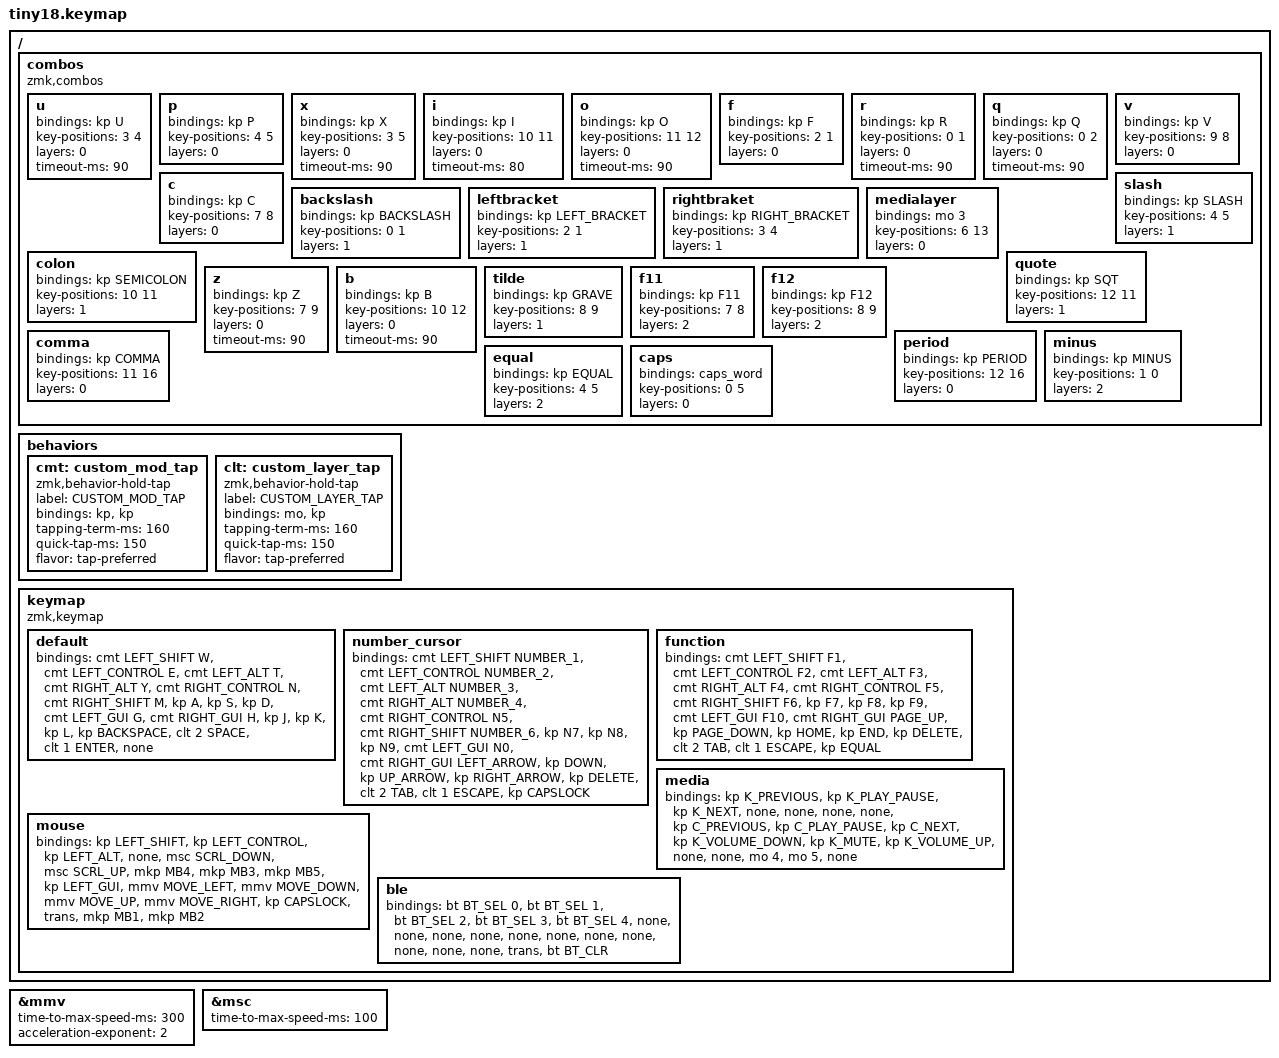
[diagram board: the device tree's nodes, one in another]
#include <input/processors.dtsi>
#include <dt-bindings/zmk/input_transform.h>
#include <zephyr/dt-bindings/input/input-event-codes.h>

#define ZMK_POINTING_DEFAULT_MOVE_VAL 2100
#define ZMK_POINTING_DEFAULT_SCRL_VAL 30

#include <behaviors.dtsi>
#include <dt-bindings/zmk/bt.h>
#include <dt-bindings/zmk/keys.h>
#include <dt-bindings/zmk/pointing.h>

&mmv {
    time-to-max-speed-ms = <300>;
    acceleration-exponent = <2>;
};

&msc { time-to-max-speed-ms = <100>; };

/ {
    combos {
        compatible = "zmk,combos";

        u {
            bindings = <&kp U>;
            key-positions = <3 4>;
            layers = <0>;
            timeout-ms = <90>;
        };

        p {
            bindings = <&kp P>;
            key-positions = <4 5>;
            layers = <0>;
        };

        x {
            bindings = <&kp X>;
            key-positions = <3 5>;
            layers = <0>;
            timeout-ms = <90>;
        };

        i {
            bindings = <&kp I>;
            key-positions = <10 11>;
            layers = <0>;
            timeout-ms = <80>;
        };

        o {
            bindings = <&kp O>;
            key-positions = <11 12>;
            layers = <0>;
            timeout-ms = <90>;
        };

        f {
            bindings = <&kp F>;
            key-positions = <2 1>;
            layers = <0>;
        };

        r {
            bindings = <&kp R>;
            key-positions = <0 1>;
            layers = <0>;
            timeout-ms = <90>;
        };

        q {
            bindings = <&kp Q>;
            key-positions = <0 2>;
            layers = <0>;
            timeout-ms = <90>;
        };

        v {
            bindings = <&kp V>;
            key-positions = <9 8>;
            layers = <0>;
        };

        c {
            bindings = <&kp C>;
            key-positions = <7 8>;
            layers = <0>;
        };

        backslash {
            bindings = <&kp BACKSLASH>;
            key-positions = <0 1>;
            layers = <1>;
        };

        leftbracket {
            bindings = <&kp LEFT_BRACKET>;
            key-positions = <2 1>;
            layers = <1>;
        };

        rightbraket {
            bindings = <&kp RIGHT_BRACKET>;
            key-positions = <3 4>;
            layers = <1>;
        };

        slash {
            bindings = <&kp SLASH>;
            key-positions = <4 5>;
            layers = <1>;
        };

        medialayer {
            bindings = <&mo 3>;
            key-positions = <6 13>;
            layers = <0>;
        };

        colon {
            bindings = <&kp SEMICOLON>;
            key-positions = <10 11>;
            layers = <1>;
        };

        quote {
            bindings = <&kp SQT>;
            key-positions = <12 11>;
            layers = <1>;
        };

        z {
            bindings = <&kp Z>;
            key-positions = <7 9>;
            layers = <0>;
            timeout-ms = <90>;
        };

        b {
            bindings = <&kp B>;
            key-positions = <10 12>;
            layers = <0>;
            timeout-ms = <90>;
        };

        tilde {
            bindings = <&kp GRAVE>;
            key-positions = <8 9>;
            layers = <1>;
        };

        f11 {
            bindings = <&kp F11>;
            key-positions = <7 8>;
            layers = <2>;
        };

        f12 {
            bindings = <&kp F12>;
            key-positions = <8 9>;
            layers = <2>;
        };

        comma {
            bindings = <&kp COMMA>;
            key-positions = <11 16>;
            layers = <0>;
        };

        period {
            bindings = <&kp PERIOD>;
            key-positions = <12 16>;
            layers = <0>;
        };

        minus {
            bindings = <&kp MINUS>;
            key-positions = <1 0>;
            layers = <2>;
        };

        equal {
            bindings = <&kp EQUAL>;
            key-positions = <4 5>;
            layers = <2>;
        };

        caps {
            bindings = <&caps_word>;
            key-positions = <0 5>;
            layers = <0>;
        };
    };

    behaviors {
        cmt: custom_mod_tap {
            compatible = "zmk,behavior-hold-tap";
            label = "CUSTOM_MOD_TAP";
            bindings = <&kp>, <&kp>;

            #binding-cells = <2>;
            tapping-term-ms = <160>;
            quick-tap-ms = <150>;
            flavor = "tap-preferred";
        };

        clt: custom_layer_tap {
            compatible = "zmk,behavior-hold-tap";
            label = "CUSTOM_LAYER_TAP";
            bindings = <&mo>, <&kp>;

            #binding-cells = <2>;
            tapping-term-ms = <160>;
            quick-tap-ms = <150>;
            flavor = "tap-preferred";
        };
    };

    keymap {
        compatible = "zmk,keymap";

        default {
            bindings = <
&cmt LEFT_SHIFT W  &cmt LEFT_CONTROL E  &cmt LEFT_ALT T  &cmt RIGHT_ALT Y  &cmt RIGHT_CONTROL N  &cmt RIGHT_SHIFT M  &kp A  &kp S  &kp D  &cmt LEFT_GUI G  &cmt RIGHT_GUI H  &kp J  &kp K  &kp L  &kp BACKSPACE  &clt 2 SPACE  &clt 1 ENTER  &none
            >;
        };

        number_cursor {
            bindings = <
&cmt LEFT_SHIFT NUMBER_1  &cmt LEFT_CONTROL NUMBER_2  &cmt LEFT_ALT NUMBER_3  &cmt RIGHT_ALT NUMBER_4  &cmt RIGHT_CONTROL N5  &cmt RIGHT_SHIFT NUMBER_6  &kp N7  &kp N8  &kp N9  &cmt LEFT_GUI N0  &cmt RIGHT_GUI LEFT_ARROW  &kp DOWN  &kp UP_ARROW  &kp RIGHT_ARROW  &kp DELETE  &clt 2 TAB  &clt 1 ESCAPE  &kp CAPSLOCK
            >;
        };

        function {
            bindings = <
&cmt LEFT_SHIFT F1  &cmt LEFT_CONTROL F2  &cmt LEFT_ALT F3  &cmt RIGHT_ALT F4  &cmt RIGHT_CONTROL F5  &cmt RIGHT_SHIFT F6  &kp F7  &kp F8  &kp F9  &cmt LEFT_GUI F10  &cmt RIGHT_GUI PAGE_UP  &kp PAGE_DOWN  &kp HOME  &kp END  &kp DELETE  &clt 2 TAB  &clt 1 ESCAPE  &kp EQUAL
            >;
        };

        media {
            bindings = <
&kp K_PREVIOUS  &kp K_PLAY_PAUSE  &kp K_NEXT  &none  &none  &none  &none  &kp C_PREVIOUS  &kp C_PLAY_PAUSE  &kp C_NEXT  &kp K_VOLUME_DOWN  &kp K_MUTE  &kp K_VOLUME_UP  &none  &none  &mo 4  &mo 5  &none
            >;
        };

        mouse {
            bindings = <
&kp LEFT_SHIFT  &kp LEFT_CONTROL  &kp LEFT_ALT  &none  &msc SCRL_DOWN  &msc SCRL_UP  &mkp MB4  &mkp MB3  &mkp MB5  &kp LEFT_GUI  &mmv MOVE_LEFT  &mmv MOVE_DOWN  &mmv MOVE_UP  &mmv MOVE_RIGHT  &kp CAPSLOCK  &trans  &mkp MB1  &mkp MB2
            >;
        };

        ble {
            bindings = <
&bt BT_SEL 0  &bt BT_SEL 1  &bt BT_SEL 2  &bt BT_SEL 3  &bt BT_SEL 4  &none  &none  &none  &none  &none  &none  &none  &none  &none  &none  &none  &trans  &bt BT_CLR
            >;
        };
    };
};
